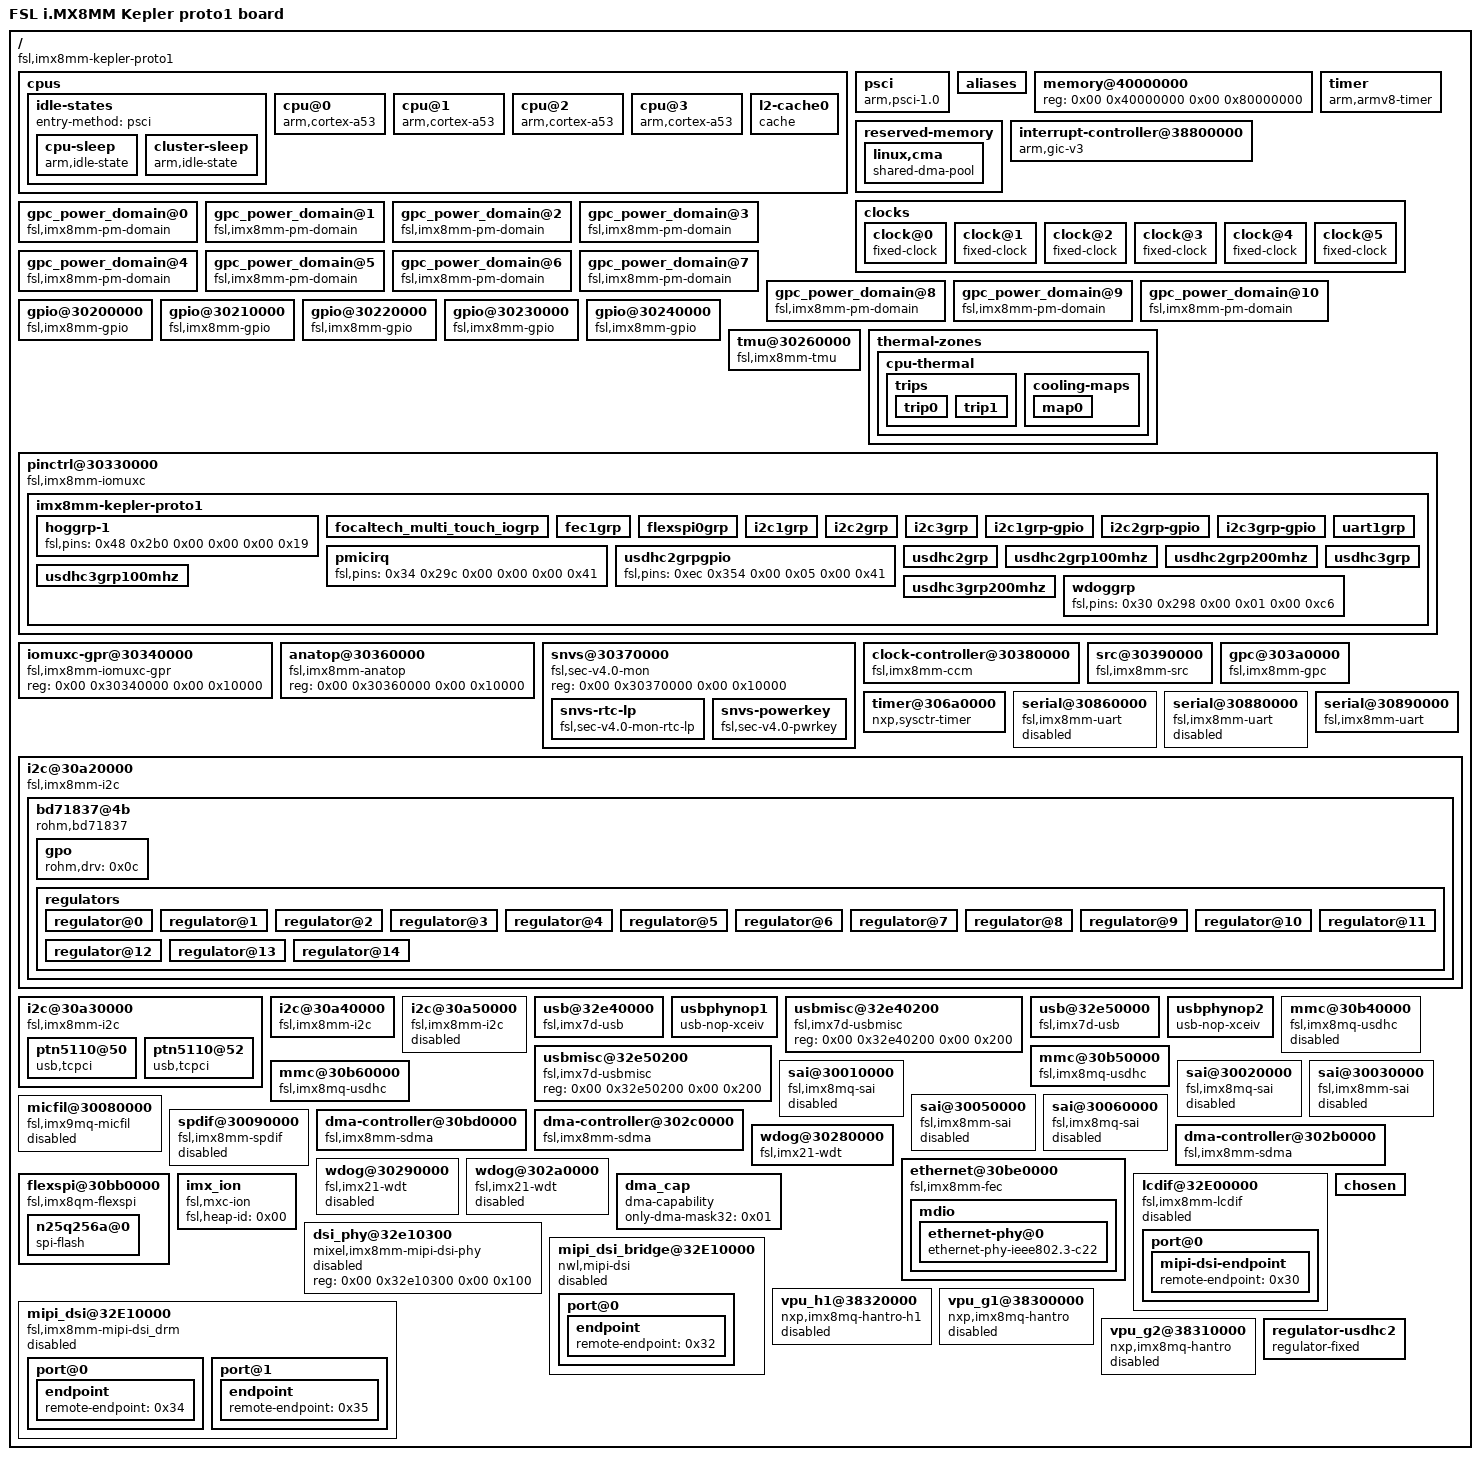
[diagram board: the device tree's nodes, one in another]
/dts-v1/;

/ {
	compatible = "fsl,imx8mm-kepler-proto1\0fsl,imx8mm";
	interrupt-parent = <0x01>;
	#address-cells = <0x02>;
	#size-cells = <0x02>;
	model = "FSL i.MX8MM Kepler proto1 board";

	cpus {
		#address-cells = <0x02>;
		#size-cells = <0x00>;

		idle-states {
			entry-method = "psci";

			cpu-sleep {
				compatible = "arm,idle-state";
				local-timer-stop;
				arm,psci-suspend-param = <0x10033>;
				entry-latency-us = <0x3e8>;
				exit-latency-us = <0x2bc>;
				min-residency-us = <0xa8c>;
				wakeup-latency-us = <0x5dc>;
				phandle = <0x03>;
			};

			cluster-sleep {
				compatible = "arm,idle-state";
				local-timer-stop;
				arm,psci-suspend-param = <0x1000000>;
				entry-latency-us = <0x3e8>;
				exit-latency-us = <0x2bc>;
				min-residency-us = <0xa8c>;
				wakeup-latency-us = <0x5dc>;
			};
		};

		cpu@0 {
			device_type = "cpu";
			compatible = "arm,cortex-a53";
			reg = <0x00 0x00>;
			enable-method = "psci";
			next-level-cache = <0x02>;
			cpu-idle-states = <0x03>;
			operating-points = <0x1b7740 0xf4240 0x186a00 0xdbba0 0x124f80 0xc3500>;
			clocks = <0x04 0x4c 0x04 0x42 0x04 0x18 0x04 0x2c 0x04 0x38>;
			clock-names = "a53\0arm_a53_src\0arm_pll\0arm_pll_out\0sys1_pll_800m";
			clock-latency = <0xee6c>;
			#cooling-cells = <0x02>;
			arm-supply = <0x05>;
			phandle = <0x09>;
		};

		cpu@1 {
			device_type = "cpu";
			compatible = "arm,cortex-a53";
			reg = <0x00 0x01>;
			enable-method = "psci";
			next-level-cache = <0x02>;
			cpu-idle-states = <0x03>;
		};

		cpu@2 {
			device_type = "cpu";
			compatible = "arm,cortex-a53";
			reg = <0x00 0x02>;
			enable-method = "psci";
			next-level-cache = <0x02>;
			cpu-idle-states = <0x03>;
		};

		cpu@3 {
			device_type = "cpu";
			compatible = "arm,cortex-a53";
			reg = <0x00 0x03>;
			enable-method = "psci";
			next-level-cache = <0x02>;
			cpu-idle-states = <0x03>;
		};

		l2-cache0 {
			compatible = "cache";
			phandle = <0x02>;
		};
	};

	psci {
		compatible = "arm,psci-1.0";
		method = "smc";
		cpu_suspend = <0xc4000001>;
		cpu_off = <0xc4000002>;
		cpu_on = <0xc4000003>;
	};

	aliases {
		ethernet0 = "/ethernet@30be0000";
		i2c0 = "/i2c@30a20000";
		i2c1 = "/i2c@30a30000";
		i2c2 = "/i2c@30a40000";
		i2c3 = "/i2c@30a50000";
		serial0 = "/serial@30860000";
		serial1 = "/serial@30890000";
		serial2 = "/serial@30880000";
		gpio0 = "/gpio@30200000";
		gpio1 = "/gpio@30210000";
		gpio2 = "/gpio@30220000";
		gpio3 = "/gpio@30230000";
		gpio4 = "/gpio@30240000";
		spi0 = "/flexspi@30bb0000";
		usb0 = "/usb@32e40000";
		usb1 = "/usb@32e50000";
	};

	memory@40000000 {
		device_type = "memory";
		reg = <0x00 0x40000000 0x00 0x80000000>;
	};

	reserved-memory {
		#address-cells = <0x02>;
		#size-cells = <0x02>;
		ranges;

		linux,cma {
			compatible = "shared-dma-pool";
			reusable;
			size = <0x00 0x28000000>;
			alloc-ranges = <0x00 0x40000000 0x00 0x80000000>;
			linux,cma-default;
		};
	};

	interrupt-controller@38800000 {
		compatible = "arm,gic-v3";
		reg = <0x00 0x38800000 0x00 0x10000 0x00 0x38880000 0x00 0xc0000>;
		#interrupt-cells = <0x03>;
		interrupt-controller;
		interrupts = <0x01 0x09 0x04>;
		interrupt-parent = <0x06>;
		phandle = <0x06>;
	};

	timer {
		compatible = "arm,armv8-timer";
		interrupts = <0x01 0x0d 0x3f08 0x01 0x0e 0x3f08 0x01 0x0b 0x3f08 0x01 0x0a 0x3f08>;
		clock-frequency = <0x7a1200>;
		interrupt-parent = <0x06>;
	};

	clocks {
		#address-cells = <0x01>;
		#size-cells = <0x00>;

		clock@0 {
			compatible = "fixed-clock";
			reg = <0x00>;
			#clock-cells = <0x00>;
			clock-frequency = <0x8000>;
			clock-output-names = "osc_32k";
			phandle = <0x0c>;
		};

		clock@1 {
			compatible = "fixed-clock";
			reg = <0x01>;
			#clock-cells = <0x00>;
			clock-frequency = <0x16e3600>;
			clock-output-names = "osc_24m";
			phandle = <0x0d>;
		};

		clock@2 {
			compatible = "fixed-clock";
			reg = <0x03>;
			#clock-cells = <0x00>;
			clock-frequency = <0x7ed6b40>;
			clock-output-names = "clk_ext1";
			phandle = <0x0e>;
		};

		clock@3 {
			compatible = "fixed-clock";
			reg = <0x04>;
			#clock-cells = <0x00>;
			clock-frequency = <0x7ed6b40>;
			clock-output-names = "clk_ext2";
			phandle = <0x0f>;
		};

		clock@4 {
			compatible = "fixed-clock";
			reg = <0x05>;
			#clock-cells = <0x00>;
			clock-frequency = <0x7ed6b40>;
			clock-output-names = "clk_ext3";
			phandle = <0x10>;
		};

		clock@5 {
			compatible = "fixed-clock";
			reg = <0x06>;
			#clock-cells = <0x00>;
			clock-frequency = <0x7ed6b40>;
			clock-output-names = "clk_ext4";
			phandle = <0x11>;
		};
	};

	gpc_power_domain@0 {
		compatible = "fsl,imx8mm-pm-domain";
		#power-domain-cells = <0x00>;
		domain-id = <0x00>;
		domain-name = "MIPI_PD";
	};

	gpc_power_domain@1 {
		compatible = "fsl,imx8mm-pm-domain";
		#power-domain-cells = <0x00>;
		domain-id = <0x01>;
		domain-name = "PCIE0_PD";
	};

	gpc_power_domain@2 {
		compatible = "fsl,imx8mm-pm-domain";
		#power-domain-cells = <0x00>;
		domain-id = <0x02>;
		domain-name = "USB_OTG1_PD";
	};

	gpc_power_domain@3 {
		compatible = "fsl,imx8mm-pm-domain";
		#power-domain-cells = <0x00>;
		domain-id = <0x03>;
		domain-name = "USB_OTG2_PD";
	};

	gpc_power_domain@4 {
		compatible = "fsl,imx8mm-pm-domain";
		#power-domain-cells = <0x00>;
		domain-id = <0x04>;
		domain-name = "GPU_2D_PD";
	};

	gpc_power_domain@5 {
		compatible = "fsl,imx8mm-pm-domain";
		#power-domain-cells = <0x00>;
		domain-id = <0x05>;
		domain-name = "GPU_MIX_PD";
	};

	gpc_power_domain@6 {
		compatible = "fsl,imx8mm-pm-domain";
		#power-domain-cells = <0x00>;
		domain-id = <0x06>;
		domain-name = "VPU_MIX_PD";
	};

	gpc_power_domain@7 {
		compatible = "fsl,imx8mm-pm-domain";
		#power-domain-cells = <0x00>;
		domain-id = <0x07>;
		domain-name = "DISP_MIX_PD";
	};

	gpc_power_domain@8 {
		compatible = "fsl,imx8mm-pm-domain";
		#power-domain-cells = <0x00>;
		domain-id = <0x08>;
		domain-name = "VPU_G1_PD";
		phandle = <0x37>;
	};

	gpc_power_domain@9 {
		compatible = "fsl,imx8mm-pm-domain";
		#power-domain-cells = <0x00>;
		domain-id = <0x09>;
		domain-name = "VPU_G2_PD";
		phandle = <0x38>;
	};

	gpc_power_domain@10 {
		compatible = "fsl,imx8mm-pm-domain";
		#power-domain-cells = <0x00>;
		domain-id = <0x0a>;
		domain-name = "VPU_H1_PD";
		phandle = <0x36>;
	};

	gpio@30200000 {
		compatible = "fsl,imx8mm-gpio\0fsl,imx35-gpio";
		reg = <0x00 0x30200000 0x00 0x10000>;
		interrupts = <0x00 0x40 0x04 0x00 0x41 0x04>;
		gpio-controller;
		#gpio-cells = <0x02>;
		interrupt-controller;
		#interrupt-cells = <0x02>;
		phandle = <0x17>;
	};

	gpio@30210000 {
		compatible = "fsl,imx8mm-gpio\0fsl,imx35-gpio";
		reg = <0x00 0x30210000 0x00 0x10000>;
		interrupts = <0x00 0x42 0x04 0x00 0x43 0x04>;
		gpio-controller;
		#gpio-cells = <0x02>;
		interrupt-controller;
		#interrupt-cells = <0x02>;
		phandle = <0x39>;
	};

	gpio@30220000 {
		compatible = "fsl,imx8mm-gpio\0fsl,imx35-gpio";
		reg = <0x00 0x30220000 0x00 0x10000>;
		interrupts = <0x00 0x44 0x04 0x00 0x45 0x04>;
		gpio-controller;
		#gpio-cells = <0x02>;
		interrupt-controller;
		#interrupt-cells = <0x02>;
	};

	gpio@30230000 {
		compatible = "fsl,imx8mm-gpio\0fsl,imx35-gpio";
		reg = <0x00 0x30230000 0x00 0x10000>;
		interrupts = <0x00 0x46 0x04 0x00 0x47 0x04>;
		gpio-controller;
		#gpio-cells = <0x02>;
		interrupt-controller;
		#interrupt-cells = <0x02>;
	};

	gpio@30240000 {
		compatible = "fsl,imx8mm-gpio\0fsl,imx35-gpio";
		reg = <0x00 0x30240000 0x00 0x10000>;
		interrupts = <0x00 0x48 0x04 0x00 0x49 0x04>;
		gpio-controller;
		#gpio-cells = <0x02>;
		interrupt-controller;
		#interrupt-cells = <0x02>;
		phandle = <0x15>;
	};

	tmu@30260000 {
		compatible = "fsl,imx8mm-tmu";
		reg = <0x00 0x30260000 0x00 0x10000>;
		interrupt = <0x00 0x31 0x04>;
		little-endian;
		u-boot,dm-pre-reloc;
		#thermal-sensor-cells = <0x00>;
		phandle = <0x07>;
	};

	thermal-zones {

		cpu-thermal {
			polling-delay-passive = <0xfa>;
			polling-delay = <0x7d0>;
			thermal-sensors = <0x07>;

			trips {

				trip0 {
					temperature = <0x14c08>;
					hysteresis = <0x7d0>;
					type = "passive";
					phandle = <0x08>;
				};

				trip1 {
					temperature = <0x17318>;
					hysteresis = <0x7d0>;
					type = "critical";
				};
			};

			cooling-maps {

				map0 {
					trip = <0x08>;
					cooling-device = <0x09 0xffffffff 0xffffffff>;
				};
			};
		};
	};

	pinctrl@30330000 {
		compatible = "fsl,imx8mm-iomuxc";
		reg = <0x00 0x30330000 0x00 0x10000>;
		pinctrl-names = "default";
		pinctrl-0 = <0x0a>;

		imx8mm-kepler-proto1 {

			hoggrp-1 {
				fsl,pins = <0x48 0x2b0 0x00 0x00 0x00 0x19>;
				phandle = <0x0a>;
			};

			focaltech_multi_touch_iogrp {
				fsl,pins = <0xac 0x314 0x00 0x05 0x00 0x1d0 0x60 0x2c8 0x00 0x00 0x00 0x19>;
			};

			fec1grp {
				fsl,pins = <0x68 0x2d0 0x00 0x00 0x00 0x03 0x6c 0x2d4 0x4c0 0x00 0x01 0x03 0x70 0x2d8 0x00 0x00 0x00 0x1f 0x74 0x2dc 0x00 0x00 0x00 0x1f 0x78 0x2e0 0x00 0x00 0x00 0x1f 0x7c 0x2e4 0x00 0x00 0x00 0x1f 0x9c 0x304 0x00 0x00 0x00 0x91 0x98 0x300 0x00 0x00 0x00 0x91 0x94 0x2fc 0x00 0x00 0x00 0x91 0x90 0x2f8 0x00 0x00 0x00 0x91 0x84 0x2ec 0x00 0x00 0x00 0x1f 0x8c 0x2f4 0x00 0x00 0x00 0x91 0x88 0x2f0 0x00 0x00 0x00 0x91 0x80 0x2e8 0x00 0x00 0x00 0x1f 0x1b4 0x41c 0x00 0x05 0x00 0x19>;
				phandle = <0x2d>;
			};

			flexspi0grp {
				fsl,pins = <0xf4 0x35c 0x00 0x01 0x00 0x1c4 0xf8 0x360 0x00 0x01 0x00 0x84 0x10c 0x374 0x00 0x01 0x00 0x84 0x110 0x378 0x00 0x01 0x00 0x84 0x114 0x37c 0x00 0x01 0x00 0x84 0x118 0x380 0x00 0x01 0x00 0x84>;
				phandle = <0x2f>;
			};

			i2c1grp {
				fsl,pins = <0x214 0x47c 0x00 0x00 0x00 0x400001c3 0x218 0x480 0x00 0x00 0x00 0x400001c3>;
				phandle = <0x13>;
			};

			i2c2grp {
				fsl,pins = <0x21c 0x484 0x00 0x00 0x00 0x400001c3 0x220 0x488 0x00 0x00 0x00 0x400001c3>;
				phandle = <0x18>;
			};

			i2c3grp {
				fsl,pins = <0x224 0x48c 0x00 0x00 0x00 0x400001c3 0x228 0x490 0x00 0x00 0x00 0x400001c3>;
				phandle = <0x1a>;
			};

			i2c1grp-gpio {
				fsl,pins = <0x214 0x47c 0x00 0x05 0x00 0x1c3 0x218 0x480 0x00 0x05 0x00 0x1c3>;
				phandle = <0x14>;
			};

			i2c2grp-gpio {
				fsl,pins = <0x21c 0x484 0x00 0x05 0x00 0x1c3 0x220 0x488 0x00 0x05 0x00 0x1c3>;
				phandle = <0x19>;
			};

			i2c3grp-gpio {
				fsl,pins = <0x224 0x48c 0x00 0x05 0x00 0x1c3 0x228 0x490 0x00 0x05 0x00 0x1c3>;
				phandle = <0x1b>;
			};

			pmicirq {
				fsl,pins = <0x34 0x29c 0x00 0x00 0x00 0x41>;
				phandle = <0x16>;
			};

			uart1grp {
				fsl,pins = <0x23c 0x4a4 0x4fc 0x00 0x00 0x49 0x240 0x4a8 0x00 0x00 0x00 0x49>;
				phandle = <0x12>;
			};

			usdhc2grpgpio {
				fsl,pins = <0xec 0x354 0x00 0x05 0x00 0x41>;
				phandle = <0x23>;
			};

			usdhc2grp {
				fsl,pins = <0xd4 0x33c 0x00 0x00 0x00 0x190 0xd8 0x340 0x00 0x00 0x00 0x1d0 0xdc 0x344 0x00 0x00 0x00 0x1d0 0xe0 0x348 0x00 0x00 0x00 0x1d0 0xe4 0x34c 0x00 0x00 0x00 0x1d0 0xe8 0x350 0x00 0x00 0x00 0x1d0 0x38 0x2a0 0x00 0x01 0x00 0x1d0>;
				phandle = <0x22>;
			};

			usdhc2grp100mhz {
				fsl,pins = <0xd4 0x33c 0x00 0x00 0x00 0x194 0xd8 0x340 0x00 0x00 0x00 0x1d4 0xdc 0x344 0x00 0x00 0x00 0x1d4 0xe0 0x348 0x00 0x00 0x00 0x1d4 0xe4 0x34c 0x00 0x00 0x00 0x1d4 0xe8 0x350 0x00 0x00 0x00 0x1d4 0x38 0x2a0 0x00 0x01 0x00 0x1d0>;
				phandle = <0x24>;
			};

			usdhc2grp200mhz {
				fsl,pins = <0xd4 0x33c 0x00 0x00 0x00 0x196 0xd8 0x340 0x00 0x00 0x00 0x1d6 0xdc 0x344 0x00 0x00 0x00 0x1d6 0xe0 0x348 0x00 0x00 0x00 0x1d6 0xe4 0x34c 0x00 0x00 0x00 0x1d6 0xe8 0x350 0x00 0x00 0x00 0x1d6 0x38 0x2a0 0x00 0x01 0x00 0x1d0>;
				phandle = <0x25>;
			};

			usdhc3grp {
				fsl,pins = <0x138 0x3a0 0x00 0x12 0x00 0x40000190 0x13c 0x3a4 0x00 0x02 0x00 0x1d0 0x11c 0x384 0x00 0x02 0x00 0x1d0 0x120 0x388 0x00 0x02 0x00 0x1d0 0x124 0x38c 0x00 0x02 0x00 0x1d0 0x128 0x390 0x00 0x02 0x00 0x1d0 0x130 0x398 0x00 0x02 0x00 0x1d0 0x100 0x368 0x00 0x02 0x00 0x1d0 0x104 0x36c 0x00 0x02 0x00 0x1d0 0x108 0x370 0x00 0x02 0x00 0x1d0 0xfc 0x364 0x00 0x02 0x00 0x190>;
				phandle = <0x27>;
			};

			usdhc3grp100mhz {
				fsl,pins = <0x138 0x3a0 0x00 0x12 0x00 0x40000194 0x13c 0x3a4 0x00 0x02 0x00 0x1d4 0x11c 0x384 0x00 0x02 0x00 0x1d4 0x120 0x388 0x00 0x02 0x00 0x1d4 0x124 0x38c 0x00 0x02 0x00 0x1d4 0x128 0x390 0x00 0x02 0x00 0x1d4 0x130 0x398 0x00 0x02 0x00 0x1d4 0x100 0x368 0x00 0x02 0x00 0x1d4 0x104 0x36c 0x00 0x02 0x00 0x1d4 0x108 0x370 0x00 0x02 0x00 0x1d4 0xfc 0x364 0x00 0x02 0x00 0x194>;
				phandle = <0x28>;
			};

			usdhc3grp200mhz {
				fsl,pins = <0x138 0x3a0 0x00 0x12 0x00 0x40000196 0x13c 0x3a4 0x00 0x02 0x00 0x1d6 0x11c 0x384 0x00 0x02 0x00 0x1d6 0x120 0x388 0x00 0x02 0x00 0x1d6 0x124 0x38c 0x00 0x02 0x00 0x1d6 0x128 0x390 0x00 0x02 0x00 0x1d6 0x130 0x398 0x00 0x02 0x00 0x1d6 0x100 0x368 0x00 0x02 0x00 0x1d6 0x104 0x36c 0x00 0x02 0x00 0x1d6 0x108 0x370 0x00 0x02 0x00 0x1d6 0xfc 0x364 0x00 0x02 0x00 0x196>;
				phandle = <0x29>;
			};

			wdoggrp {
				fsl,pins = <0x30 0x298 0x00 0x01 0x00 0xc6>;
				phandle = <0x2b>;
			};
		};
	};

	iomuxc-gpr@30340000 {
		compatible = "fsl,imx8mm-iomuxc-gpr\0fsl,imx7d-iomuxc-gpr\0syscon";
		reg = <0x00 0x30340000 0x00 0x10000>;
		phandle = <0x2c>;
	};

	anatop@30360000 {
		compatible = "fsl,imx8mm-anatop\0syscon\0simple-bus";
		reg = <0x00 0x30360000 0x00 0x10000>;
	};

	snvs@30370000 {
		compatible = "fsl,sec-v4.0-mon\0syscon\0simple-mfd";
		reg = <0x00 0x30370000 0x00 0x10000>;
		phandle = <0x0b>;

		snvs-rtc-lp {
			compatible = "fsl,sec-v4.0-mon-rtc-lp";
			regmap = <0x0b>;
			offset = <0x34>;
			interrupts = <0x00 0x13 0x04 0x00 0x14 0x04>;
		};

		snvs-powerkey {
			compatible = "fsl,sec-v4.0-pwrkey";
			regmap = <0x0b>;
			interrupts = <0x00 0x04 0x04>;
			linux,keycode = <0x74>;
			wakeup-source;
		};
	};

	clock-controller@30380000 {
		compatible = "fsl,imx8mm-ccm";
		reg = <0x00 0x30380000 0x00 0x10000>;
		#clock-cells = <0x01>;
		clocks = <0x0c 0x0d 0x0e 0x0f 0x10 0x11>;
		clock-names = "osc_32k\0osc_24m\0clk_ext1\0clk_ext2\0clk_ext3\0clk_ext4";
		phandle = <0x04>;
	};

	src@30390000 {
		compatible = "fsl,imx8mm-src\0fsl,imx8mq-src\0syscon";
		reg = <0x00 0x30390000 0x00 0x10000>;
		interrupts = <0x00 0x59 0x04>;
		#reset-cells = <0x01>;
		phandle = <0x33>;
	};

	gpc@303a0000 {
		compatible = "fsl,imx8mm-gpc\0fsl,imx8mq-gpc\0syscon";
		reg = <0x00 0x303a0000 0x00 0x10000>;
		interrupt-controller;
		interrupts = <0x00 0x57 0x04>;
		#interrupt-cells = <0x03>;
		interrupt-parent = <0x06>;
		phandle = <0x01>;
	};

	timer@306a0000 {
		compatible = "nxp,sysctr-timer";
		reg = <0x00 0x306a0000 0x00 0x10000 0x00 0x306b0000 0x00 0x10000 0x00 0x306c0000 0x00 0x10000>;
		clock-frequency = <0x7a1200>;
		interrupts = <0x00 0x2f 0x04 0x00 0x30 0x04>;
	};

	serial@30860000 {
		compatible = "fsl,imx8mm-uart\0fsl,imx6q-uart\0fsl,imx21-uart";
		reg = <0x00 0x30860000 0x00 0x10000>;
		interrupts = <0x00 0x1a 0x04>;
		interrupt-parent = <0x01>;
		clocks = <0x04 0x1a1 0x04 0x1a1>;
		clock-names = "ipg\0per";
		status = "disabled";
	};

	serial@30880000 {
		compatible = "fsl,imx8mm-uart\0fsl,imx6q-uart\0fsl,imx21-uart";
		reg = <0x00 0x30880000 0x00 0x10000>;
		interrupts = <0x00 0x1c 0x04>;
		interrupt-parent = <0x01>;
		clocks = <0x04 0x1a3 0x04 0x1a3>;
		clock-names = "ipg\0per";
		status = "disabled";
	};

	serial@30890000 {
		compatible = "fsl,imx8mm-uart\0fsl,imx6q-uart\0fsl,imx21-uart";
		reg = <0x00 0x30890000 0x00 0x10000>;
		interrupts = <0x00 0x1b 0x04>;
		interrupt-parent = <0x01>;
		clocks = <0x04 0x1a2 0x04 0x1a2>;
		clock-names = "ipg\0per";
		status = "okay";
		pinctrl-names = "default";
		pinctrl-0 = <0x12>;
	};

	i2c@30a20000 {
		#address-cells = <0x01>;
		#size-cells = <0x00>;
		compatible = "fsl,imx8mm-i2c\0fsl,imx21-i2c";
		reg = <0x00 0x30a20000 0x00 0x10000>;
		interrupts = <0x00 0x23 0x04>;
		clocks = <0x04 0x189>;
		status = "okay";
		clock-frequency = <0x61a80>;
		pinctrl-names = "default\0gpio";
		pinctrl-0 = <0x13>;
		pinctrl-1 = <0x14>;
		scl-gpios = <0x15 0x0e 0x00>;
		sda-gpios = <0x15 0x0f 0x00>;

		bd71837@4b {
			reg = <0x4b>;
			compatible = "rohm,bd71837";
			pinctrl-0 = <0x16>;
			gpio_intr = <0x17 0x03 0x01>;

			gpo {
				rohm,drv = <0x0c>;
			};

			regulators {
				#address-cells = <0x01>;
				#size-cells = <0x00>;
				bd71837,pmic-buck2-uses-i2c-dvs;
				bd71837,pmic-buck2-dvs-voltage = <0xf4240 0xdbba0 0x00>;

				regulator@0 {
					reg = <0x00>;
					regulator-compatible = "buck1";
					regulator-min-microvolt = <0xaae60>;
					regulator-max-microvolt = <0x13d620>;
					regulator-boot-on;
					regulator-always-on;
					regulator-ramp-delay = <0x4e2>;
				};

				regulator@1 {
					reg = <0x01>;
					regulator-compatible = "buck2";
					regulator-min-microvolt = <0xaae60>;
					regulator-max-microvolt = <0x13d620>;
					regulator-boot-on;
					regulator-always-on;
					regulator-ramp-delay = <0x4e2>;
					phandle = <0x05>;
				};

				regulator@2 {
					reg = <0x02>;
					regulator-compatible = "buck3";
					regulator-min-microvolt = <0xaae60>;
					regulator-max-microvolt = <0x13d620>;
				};

				regulator@3 {
					reg = <0x03>;
					regulator-compatible = "buck4";
					regulator-min-microvolt = <0xaae60>;
					regulator-max-microvolt = <0x13d620>;
				};

				regulator@4 {
					reg = <0x04>;
					regulator-compatible = "buck5";
					regulator-min-microvolt = <0xaae60>;
					regulator-max-microvolt = <0x149970>;
					regulator-boot-on;
					regulator-always-on;
				};

				regulator@5 {
					reg = <0x05>;
					regulator-compatible = "buck6";
					regulator-min-microvolt = <0x2dc6c0>;
					regulator-max-microvolt = <0x325aa0>;
					regulator-boot-on;
					regulator-always-on;
				};

				regulator@6 {
					reg = <0x06>;
					regulator-compatible = "buck7";
					regulator-min-microvolt = <0x187d88>;
					regulator-max-microvolt = <0x1e70f8>;
					regulator-boot-on;
					regulator-always-on;
				};

				regulator@7 {
					reg = <0x07>;
					regulator-compatible = "buck8";
					regulator-min-microvolt = "\0\f5";
					regulator-max-microvolt = <0x155cc0>;
					regulator-boot-on;
					regulator-always-on;
				};

				regulator@8 {
					reg = <0x08>;
					regulator-compatible = "ldo1";
					regulator-min-microvolt = <0x2dc6c0>;
					regulator-max-microvolt = <0x325aa0>;
					regulator-boot-on;
					regulator-always-on;
				};

				regulator@9 {
					reg = <0x09>;
					regulator-compatible = "ldo2";
					regulator-min-microvolt = <0xdbba0>;
					regulator-max-microvolt = <0xdbba0>;
					regulator-boot-on;
					regulator-always-on;
				};

				regulator@10 {
					reg = <0x0a>;
					regulator-compatible = "ldo3";
					regulator-min-microvolt = <0x1b7740>;
					regulator-max-microvolt = <0x325aa0>;
					regulator-boot-on;
					regulator-always-on;
				};

				regulator@11 {
					reg = <0x0b>;
					regulator-compatible = "ldo4";
					regulator-min-microvolt = <0xdbba0>;
					regulator-max-microvolt = <0x1b7740>;
					regulator-boot-on;
					regulator-always-on;
				};

				regulator@12 {
					reg = <0x0c>;
					regulator-compatible = "ldo5";
					regulator-min-microvolt = <0x1b7740>;
					regulator-max-microvolt = <0x325aa0>;
				};

				regulator@13 {
					reg = <0x0d>;
					regulator-compatible = "ldo6";
					regulator-min-microvolt = <0xdbba0>;
					regulator-max-microvolt = <0x1b7740>;
					regulator-boot-on;
					regulator-always-on;
				};

				regulator@14 {
					reg = <0x0e>;
					regulator-compatible = "ldo7";
					regulator-min-microvolt = <0x1b7740>;
					regulator-max-microvolt = <0x325aa0>;
				};
			};
		};
	};

	i2c@30a30000 {
		#address-cells = <0x01>;
		#size-cells = <0x00>;
		compatible = "fsl,imx8mm-i2c\0fsl,imx21-i2c";
		reg = <0x00 0x30a30000 0x00 0x10000>;
		interrupts = <0x00 0x24 0x04>;
		clocks = <0x04 0x18a>;
		status = "okay";
		clock-frequency = <0x61a80>;
		pinctrl-names = "default\0gpio";
		pinctrl-0 = <0x18>;
		pinctrl-1 = <0x19>;
		scl-gpios = <0x15 0x10 0x00>;
		sda-gpios = <0x15 0x11 0x00>;

		ptn5110@50 {
			compatible = "usb,tcpci";
			reg = <0x50>;
			src-pdos = <0x380190c8>;
			snk-pdos = <0x380190c8 0x3802d0c8>;
			max-snk-mv = <0x2328>;
			max-snk-ma = <0x7d0>;
			op-snk-mw = <0x2328>;
			max-snk-mw = <0x4650>;
			port-type = "drp";
			default-role = "sink";
			phandle = <0x1e>;
		};

		ptn5110@52 {
			compatible = "usb,tcpci";
			reg = <0x52>;
			src-pdos = <0x380190c8>;
			snk-pdos = <0x380190c8 0x3802d0c8>;
			max-snk-mv = <0x2328>;
			max-snk-ma = <0x7d0>;
			op-snk-mw = <0x2328>;
			max-snk-mw = <0x4650>;
			port-type = "drp";
			default-role = "sink";
			phandle = <0x21>;
		};
	};

	i2c@30a40000 {
		#address-cells = <0x01>;
		#size-cells = <0x00>;
		compatible = "fsl,imx8mm-i2c\0fsl,imx21-i2c";
		reg = <0x00 0x30a40000 0x00 0x10000>;
		interrupts = <0x00 0x25 0x04>;
		clocks = <0x04 0x18b>;
		status = "okay";
		clock-frequency = <0x186a0>;
		pinctrl-names = "default\0gpio";
		pinctrl-0 = <0x1a>;
		pinctrl-1 = <0x1b>;
		scl-gpios = <0x15 0x12 0x00>;
		sda-gpios = <0x15 0x13 0x00>;
	};

	i2c@30a50000 {
		#address-cells = <0x01>;
		#size-cells = <0x00>;
		compatible = "fsl,imx8mm-i2c\0fsl,imx21-i2c";
		reg = <0x00 0x30a50000 0x00 0x10000>;
		interrupts = <0x00 0x26 0x04>;
		clocks = <0x04 0x18c>;
		status = "disabled";
	};

	usb@32e40000 {
		compatible = "fsl,imx7d-usb\0fsl,imx27-usb";
		reg = <0x00 0x32e40000 0x00 0x200>;
		interrupts = <0x00 0x28 0x04>;
		clocks = <0x04 0x1a5>;
		clock-names = "usb1_ctrl_root_clk";
		assigned-clocks = <0x04 0x58 0x04 0xb2>;
		assigned-clock-parents = <0x04 0x40 0x04 0x32>;
		fsl,usbphy = <0x1c>;
		fsl,usbmisc = <0x1d 0x00>;
		status = "okay";
		extcon = <0x1e>;
		dr_mode = "peripheral";
	};

	usbphynop1 {
		compatible = "usb-nop-xceiv";
		clocks = <0x04 0xb3>;
		assigned-clocks = <0x04 0xb3>;
		assigned-clock-parents = <0x04 0x32>;
		clock-names = "main_clk";
		phandle = <0x1c>;
	};

	usbmisc@32e40200 {
		#index-cells = <0x01>;
		compatible = "fsl,imx7d-usbmisc\0fsl,imx6q-usbmisc";
		reg = <0x00 0x32e40200 0x00 0x200>;
		phandle = <0x1d>;
	};

	usb@32e50000 {
		compatible = "fsl,imx7d-usb\0fsl,imx27-usb";
		reg = <0x00 0x32e50000 0x00 0x200>;
		interrupts = <0x00 0x29 0x04>;
		clocks = <0x04 0x1a5>;
		clock-names = "usb1_ctrl_root_clk";
		assigned-clocks = <0x04 0x58 0x04 0xb2>;
		assigned-clock-parents = <0x04 0x40 0x04 0x32>;
		fsl,usbphy = <0x1f>;
		fsl,usbmisc = <0x20 0x00>;
		status = "okay";
		extcon = <0x21>;
		dr_mode = "host";
	};

	usbphynop2 {
		compatible = "usb-nop-xceiv";
		clocks = <0x04 0xb3>;
		assigned-clocks = <0x04 0xb3>;
		assigned-clock-parents = <0x04 0x32>;
		clock-names = "main_clk";
		phandle = <0x1f>;
	};

	usbmisc@32e50200 {
		#index-cells = <0x01>;
		compatible = "fsl,imx7d-usbmisc\0fsl,imx6q-usbmisc";
		reg = <0x00 0x32e50200 0x00 0x200>;
		phandle = <0x20>;
	};

	mmc@30b40000 {
		compatible = "fsl,imx8mq-usdhc\0fsl,imx7d-usdhc";
		reg = <0x00 0x30b40000 0x00 0x10000>;
		interrupts = <0x00 0x16 0x04>;
		clocks = <0x04 0x00 0x04 0x77 0x04 0x1a7>;
		clock-names = "ipg\0ahb\0per";
		assigned-clocks = <0x04 0x15f>;
		assigned-clock-rates = <0x17d78400>;
		fsl,tuning-start-tap = <0x14>;
		fsl,tuning-step = <0x02>;
		bus-width = <0x04>;
		status = "disabled";
	};

	mmc@30b50000 {
		compatible = "fsl,imx8mq-usdhc\0fsl,imx7d-usdhc";
		reg = <0x00 0x30b50000 0x00 0x10000>;
		interrupts = <0x00 0x17 0x04>;
		clocks = <0x04 0x00 0x04 0x77 0x04 0x1a8>;
		clock-names = "ipg\0ahb\0per";
		fsl,tuning-start-tap = <0x14>;
		fsl,tuning-step = <0x02>;
		bus-width = <0x04>;
		status = "okay";
		pinctrl-names = "default\0state_100mhz\0state_200mhz";
		pinctrl-0 = <0x22 0x23>;
		pinctrl-1 = <0x24 0x23>;
		pinctrl-2 = <0x25 0x23>;
		non-removable;
		vmmc-supply = <0x26>;
	};

	mmc@30b60000 {
		compatible = "fsl,imx8mq-usdhc\0fsl,imx7d-usdhc";
		reg = <0x00 0x30b60000 0x00 0x10000>;
		interrupts = <0x00 0x18 0x04>;
		clocks = <0x04 0x00 0x04 0x77 0x04 0x1b5>;
		clock-names = "ipg\0ahb\0per";
		assigned-clocks = <0x04 0x1b5>;
		assigned-clock-rates = <0x17d78400>;
		fsl,tuning-start-tap = <0x14>;
		fsl,tuning-step = <0x02>;
		bus-width = <0x08>;
		status = "okay";
		pinctrl-names = "default\0state_100mhz\0state_200mhz";
		pinctrl-0 = <0x27>;
		pinctrl-1 = <0x28>;
		pinctrl-2 = <0x29>;
		non-removable;
	};

	sai@30010000 {
		compatible = "fsl,imx8mq-sai\0fsl,imx6sx-sai";
		reg = <0x00 0x30010000 0x00 0x10000>;
		interrupts = <0x00 0x5f 0x04>;
		clocks = <0x04 0x196 0x04 0x00 0x04 0x195 0x04 0x00 0x04 0x00>;
		clock-names = "bus\0mclk0\0mclk1\0mclk2\0mclk3";
		dmas = <0x2a 0x00 0x18 0x00 0x2a 0x01 0x18 0x00>;
		dma-names = "rx\0tx";
		fsl,dataline = <0xff 0xff>;
		status = "disabled";
	};

	sai@30020000 {
		compatible = "fsl,imx8mq-sai\0fsl,imx6sx-sai";
		reg = <0x00 0x30020000 0x00 0x10000>;
		interrupts = <0x00 0x60 0x04>;
		clocks = <0x04 0x198 0x04 0x00 0x04 0x197 0x04 0x00 0x04 0x00>;
		clock-names = "bus\0mclk0\0mclk1\0mclk2\0mclk3";
		dmas = <0x2a 0x02 0x18 0x00 0x2a 0x03 0x18 0x00>;
		dma-names = "rx\0tx";
		status = "disabled";
	};

	sai@30030000 {
		compatible = "fsl,imx8mm-sai\0fsl,imx8mq-sai\0fsl,imx6sx-sai";
		reg = <0x00 0x30030000 0x00 0x10000>;
		interrupts = <0x00 0x32 0x04>;
		clocks = <0x04 0x19a 0x04 0x00 0x04 0x199 0x04 0x00 0x04 0x00>;
		clock-names = "bus\0mclk0\0mclk1\0mclk2\0mclk3";
		dmas = <0x2a 0x04 0x18 0x00 0x2a 0x05 0x18 0x00>;
		dma-names = "rx\0tx";
		status = "disabled";
	};

	sai@30050000 {
		compatible = "fsl,imx8mm-sai\0fsl,imx8mq-sai\0fsl,imx6sx-sai";
		reg = <0x00 0x30050000 0x00 0x10000>;
		interrupts = <0x00 0x5a 0x04>;
		clocks = <0x04 0x19e 0x04 0x00 0x04 0x19d 0x04 0x00 0x04 0x00>;
		clock-names = "bus\0mclk0\0mclk1\0mclk2\0mclk3";
		dmas = <0x2a 0x08 0x18 0x00 0x2a 0x09 0x18 0x00>;
		dma-names = "rx\0tx";
		fsl,shared-interrupt;
		fsl,dataline = <0x0f 0x0f>;
		status = "disabled";
	};

	sai@30060000 {
		compatible = "fsl,imx8mq-sai\0fsl,imx6sx-sai";
		reg = <0x00 0x30060000 0x00 0x10000>;
		interrupts = <0x00 0x5a 0x04>;
		clocks = <0x04 0x1a0 0x04 0x00 0x04 0x19f 0x04 0x00 0x04 0x00>;
		clock-names = "bus\0mclk0\0mclk1\0mclk2\0mclk3";
		dmas = <0x2a 0x0a 0x18 0x00 0x2a 0x0b 0x18 0x00>;
		dma-names = "rx\0tx";
		fsl,shared-interrupt;
		status = "disabled";
	};

	micfil@30080000 {
		compatible = "fsl,imx9mq-micfil";
		reg = <0x00 0x30080000 0x00 0x10000>;
		interrupts = <0x00 0x2c 0x04 0x00 0x2d 0x04 0x00 0x6d 0x04 0x00 0x6e 0x04>;
		clocks = <0x04 0x1bd 0x04 0x1b0>;
		clock-names = "ipg_clk\0ipg_clk_app";
		dmas = <0x2a 0x18 0x18 0x00>;
		dma-names = "rx";
		status = "disabled";
	};

	spdif@30090000 {
		compatible = "fsl,imx8mm-spdif\0fsl,imx8mq-spdif\0fsl,imx35-spdif";
		reg = <0x00 0x30090000 0x00 0x10000>;
		interrupts = <0x00 0x06 0x04>;
		clocks = <0x04 0x8e 0x04 0x02 0x04 0x158 0x04 0x00 0x04 0x00 0x04 0x00 0x04 0x8e 0x04 0x00 0x04 0x00 0x04 0x00>;
		clock-names = "core\0rxtx0\0rxtx1\0rxtx2\0rxtx3\0rxtx4\0rxtx5\0rxtx6\0rxtx7\0spba";
		dmas = <0x2a 0x1c 0x12 0x00 0x2a 0x1d 0x12 0x00>;
		dma-names = "rx\0tx";
		status = "disabled";
	};

	dma-controller@30bd0000 {
		compatible = "fsl,imx8mm-sdma\0fsl,imx8mq-sdma\0fsl,imx7d-sdma";
		reg = <0x00 0x30bd0000 0x00 0x10000>;
		interrupts = <0x00 0x02 0x04>;
		clocks = <0x04 0x1b8 0x04 0x1b8>;
		clock-names = "ipg\0ahb";
		#dma-cells = <0x03>;
		fsl,sdma-ram-script-name = "imx/sdma/sdma-imx7d.bin";
		status = "okay";
	};

	dma-controller@302c0000 {
		compatible = "fsl,imx8mm-sdma\0fsl,imx8mq-sdma\0fsl,imx7d-sdma";
		reg = <0x00 0x302c0000 0x00 0x10000>;
		interrupts = <0x00 0x67 0x04>;
		clocks = <0x04 0x1b9 0x04 0x1b9>;
		clock-names = "ipg\0ahb";
		#dma-cells = <0x03>;
		fsl,sdma-ram-script-name = "imx/sdma/sdma-imx7d.bin";
		fsl,ratio-1-1;
		status = "okay";
		phandle = <0x2a>;
	};

	dma-controller@302b0000 {
		compatible = "fsl,imx8mm-sdma\0fsl,imx8mq-sdma\0fsl,imx7d-sdma";
		reg = <0x00 0x302b0000 0x00 0x10000>;
		interrupts = <0x00 0x22 0x04>;
		clocks = <0x04 0x1ba 0x04 0x1ba>;
		clock-names = "ipg\0ahb";
		#dma-cells = <0x03>;
		fsl,sdma-ram-script-name = "imx/sdma/sdma-imx7d.bin";
		fsl,ratio-1-1;
		status = "okay";
	};

	wdog@30280000 {
		compatible = "fsl,imx21-wdt";
		reg = <0x00 0x30280000 0x00 0x10000>;
		interrupts = <0x00 0x4e 0x04>;
		clocks = <0x04 0x1a9>;
		status = "okay";
		pinctrl-names = "default";
		pinctrl-0 = <0x2b>;
		fsl,ext-reset-output;
	};

	wdog@30290000 {
		compatible = "fsl,imx21-wdt";
		reg = <0x00 0x30290000 0x00 0x10000>;
		interrupts = <0x00 0x4f 0x04>;
		clocks = <0x04 0x1aa>;
		status = "disabled";
	};

	wdog@302a0000 {
		compatible = "fsl,imx21-wdt";
		reg = <0x00 0x302a0000 0x00 0x10000>;
		interrupts = <0x00 0x0a 0x04>;
		clocks = <0x04 0x1ab>;
		status = "disabled";
	};

	ethernet@30be0000 {
		compatible = "fsl,imx8mm-fec\0fsl,imx8mq-fec\0fsl,imx6sx-fec";
		reg = <0x00 0x30be0000 0x00 0x10000>;
		interrupts = <0x00 0x76 0x04 0x00 0x77 0x04 0x00 0x78 0x04>;
		clocks = <0x04 0x187 0x04 0x187 0x04 0x15b 0x04 0x15a 0x04 0x15c>;
		clock-names = "ipg\0ahb\0ptp\0enet_clk_ref\0enet_out";
		assigned-clocks = <0x04 0x52 0x04 0xa4 0x04 0xa3 0x04 0x15b>;
		assigned-clock-parents = <0x04 0x36 0x04 0x3a 0x04 0x3b>;
		assigned-clock-rates = <0x00 0x00 0x7735940 0x5f5e100>;
		stop-mode = <0x2c 0x10 0x03>;
		fsl,num-tx-queues = <0x03>;
		fsl,num-rx-queues = <0x03>;
		fsl,wakeup_irq = <0x02>;
		status = "okay";
		pinctrl-names = "default";
		pinctrl-0 = <0x2d>;
		phy-mode = "rgmii-id";
		phy-handle = <0x2e>;
		fsl,magic-packet;

		mdio {
			#address-cells = <0x01>;
			#size-cells = <0x00>;

			ethernet-phy@0 {
				compatible = "ethernet-phy-ieee802.3-c22";
				reg = <0x00>;
				at803x,led-act-blind-workaround;
				at803x,eee-okay;
				at803x,vddio-1p8v;
				phandle = <0x2e>;
			};
		};
	};

	flexspi@30bb0000 {
		#address-cells = <0x01>;
		#size-cells = <0x00>;
		compatible = "fsl,imx8qm-flexspi";
		reg = <0x00 0x30bb0000 0x00 0x10000 0x00 0x8000000 0x00 0x19ffffff>;
		reg-names = "FlexSPI\0FlexSPI-memory";
		interrupts = <0x00 0x6b 0x04>;
		clocks = <0x04 0x193 0x04 0x193>;
		clock-names = "qspi_en\0qspi";
		status = "okay";
		pinctrl-names = "default";
		pinctrl-0 = <0x2f>;

		n25q256a@0 {
			reg = <0x00>;
			#address-cells = <0x01>;
			#size-cells = <0x01>;
			compatible = "spi-flash";
			spi-max-frequency = <0x1ba8140>;
			spi-nor,ddr-quad-read-dummy = <0x08>;
		};
	};

	dma_cap {
		compatible = "dma-capability";
		only-dma-mask32 = <0x01>;
	};

	imx_ion {
		compatible = "fsl,mxc-ion";
		fsl,heap-id = <0x00>;
	};

	lcdif@32E00000 {
		compatible = "fsl,imx8mm-lcdif\0fsl,imx28-lcdif";
		reg = <0x00 0x32e00000 0x00 0x10000>;
		clocks = <0x04 0x151>;
		clock-names = "pix";
		assigned-clocks = <0x04 0x9a>;
		assigned-clock-parents = <0x04 0x28>;
		assigned-clock-rate = <0x2367b880>;
		interrupts = <0x00 0x05 0x04>;
		max-res = <0x780 0x438>;
		status = "disabled";

		port@0 {

			mipi-dsi-endpoint {
				remote-endpoint = <0x30>;
				phandle = <0x35>;
			};
		};
	};

	dsi_phy@32e10300 {
		compatible = "mixel,imx8mm-mipi-dsi-phy\0mixel,imx8mq-mipi-dsi-phy";
		reg = <0x00 0x32e10300 0x00 0x100>;
		#phy-cells = <0x00>;
		status = "disabled";
		phandle = <0x31>;
	};

	mipi_dsi_bridge@32E10000 {
		compatible = "nwl,mipi-dsi";
		reg = <0x00 0x32e10000 0x00 0x400>;
		interrupts = <0x00 0x12 0x04>;
		clocks = <0x04 0x175 0x04 0x8c 0x04 0x8f>;
		clock-names = "phy_ref\0rx_esc\0tx_esc";
		assigned-clocks = <0x04 0x83>;
		assigned-clock-parents = <0x04 0x31>;
		assigned-clock-rates = <0x4c4b400>;
		phys = <0x31>;
		phy-names = "dphy";
		status = "disabled";

		port@0 {

			endpoint {
				remote-endpoint = <0x32>;
				phandle = <0x34>;
			};
		};
	};

	mipi_dsi@32E10000 {
		compatible = "fsl,imx8mm-mipi-dsi_drm\0fsl,imx8mq-mipi-dsi_drm";
		clocks = <0x04 0x174 0x04 0x175>;
		clock-names = "core\0phy_ref";
		assigned-clocks = <0x04 0xbd 0x04 0xbe>;
		assigned-clock-parents = <0x04 0x36 0x04 0x28>;
		assigned-clock-rates = <0xfdad680 0x2367b880>;
		src = <0x33>;
		mux-sel = <0x2c>;
		phys = <0x31>;
		phys-names = "dphy";
		status = "disabled";

		port@0 {

			endpoint {
				remote-endpoint = <0x34>;
				phandle = <0x32>;
			};
		};

		port@1 {

			endpoint {
				remote-endpoint = <0x35>;
				phandle = <0x30>;
			};
		};
	};

	vpu_h1@38320000 {
		compatible = "nxp,imx8mq-hantro-h1";
		reg = <0x00 0x38320000 0x00 0x10000>;
		reg-names = "regs_hantro_h1";
		interrupts = <0x00 0x1e 0x04>;
		interrupt-names = "irq_hantro_h1";
		clocks = <0x04 0x1ae>;
		clock-names = "clk_hantro_h1";
		power-domains = <0x36>;
		assigned-clocks = <0x04 0xcc>;
		assigned-clock-parents = <0x04 0x2b>;
		assigned-clock-rates = <0x23c34600>;
		status = "disabled";
	};

	vpu_g1@38300000 {
		compatible = "nxp,imx8mq-hantro";
		reg = <0x00 0x38300000 0x00 0x100000>;
		reg-names = "regs_hantro";
		interrupts = <0x00 0x07 0x04>;
		interrupt-names = "irq_hantro";
		clocks = <0x04 0x1ac 0x04 0x1b7>;
		clock-names = "clk_hantro\0clk_hantro_bus";
		assigned-clocks = <0x04 0x92 0x04 0x54>;
		assigned-clock-parents = <0x04 0x2b 0x04 0x38>;
		assigned-clock-rates = <0x23c34600 0x2faf0800>;
		power-domains = <0x37>;
		status = "disabled";
	};

	vpu_g2@38310000 {
		compatible = "nxp,imx8mq-hantro";
		reg = <0x00 0x38310000 0x00 0x100000>;
		reg-names = "regs_hantro";
		interrupts = <0x00 0x08 0x04>;
		interrupt-names = "irq_hantro";
		clocks = <0x04 0x1af 0x04 0x1b7>;
		clock-names = "clk_hantro\0clk_hantro_bus";
		assigned-clocks = <0x04 0x93 0x04 0x54>;
		assigned-clock-parents = <0x04 0x2b 0x04 0x38>;
		assigned-clock-rates = <0x23c34600 0x2faf0800>;
		power-domains = <0x38>;
		status = "disabled";
	};

	chosen {
		bootargs = "console=ttymxc1,115200 earlycon=ec_imx6q,0x30890000,115200";
		stdout-patch = "/serial@30890000";
	};

	regulator-usdhc2 {
		compatible = "regulator-fixed";
		regulator-name = "VSD_3V3";
		regulator-min-microvolt = <0x325aa0>;
		regulator-max-microvolt = <0x325aa0>;
		gpio = <0x39 0x13 0x00>;
		enable-active-high;
		startup-delay-us = <0x64>;
		off-on-delay-us = <0x2ee0>;
		phandle = <0x26>;
	};
};
